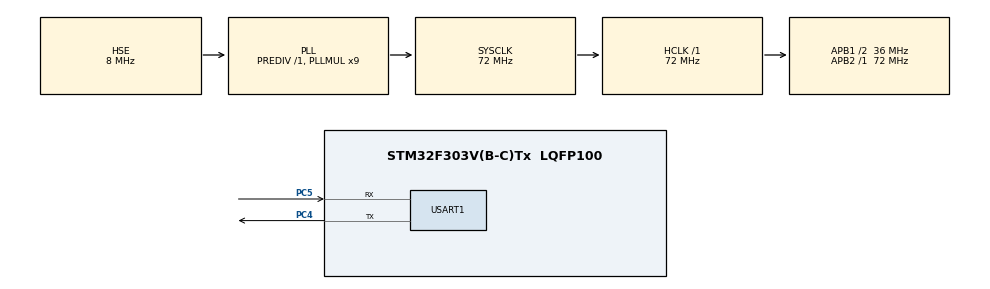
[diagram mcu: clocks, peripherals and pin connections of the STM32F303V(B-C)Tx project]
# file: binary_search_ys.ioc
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Mcu.Family=STM32F3
Mcu.Name=STM32F303V(B-C)Tx
Mcu.Package=LQFP100
NVIC.PriorityGroup=NVIC_PRIORITYGROUP_4
NVIC.TIM2_IRQn=true\:0\:0\:false\:false\:true\:true\:true
PA13.Mode=Serial_Wire
PA13.Signal=SYS_JTMS-SWDIO
PA14.Mode=Serial_Wire
PA14.Signal=SYS_JTCK-SWCLK
PC4.Mode=Asynchronous
PC4.Signal=USART1_TX
PC5.Mode=Asynchronous
PC5.Signal=USART1_RX
PF0-OSC_IN.Mode=HSE-External-Oscillator
PF0-OSC_IN.Signal=RCC_OSC_IN
PF1-OSC_OUT.Mode=HSE-External-Oscillator
PF1-OSC_OUT.Signal=RCC_OSC_OUT
ProjectManager.HeapSize=0x200
ProjectManager.StackSize=0x400
ProjectManager.TargetToolchain=STM32CubeIDE
RCC.AHBFreq_Value=72000000
RCC.APB1CLKDivider=RCC_HCLK_DIV2
RCC.APB1Freq_Value=36000000
RCC.APB1TimFreq_Value=72000000
RCC.APB2Freq_Value=72000000
RCC.APB2TimFreq_Value=72000000
RCC.CortexFreq_Value=72000000
RCC.HCLKFreq_Value=72000000
RCC.HSE_VALUE=8000000
RCC.HSI_VALUE=8000000
RCC.LSE_VALUE=32768
RCC.PLLMUL=RCC_PLL_MUL9
RCC.PLLSourceVirtual=RCC_PLLSOURCE_HSE
RCC.SYSCLKFreq_VALUE=72000000
RCC.SYSCLKSourceVirtual=RCC_SYSCLKSOURCE_PLLCLK
RCC.USBFreq_Value=72000000
TIM2.AutoReloadPreload=TIM_AUTORELOAD_PRELOAD_ENABLE
TIM2.Period=4294967295
TIM2.Prescaler=0
USART1.Parity=PARITY_EVEN
USART1.VirtualMode-Asynchronous=VM_ASYNC
VP_TIM2_VS_ClockSourceINT.Mode=Internal
board=custom

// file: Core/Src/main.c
/* USER CODE BEGIN Header */
/**
  ******************************************************************************
  * @file           : main.c
  * @brief          : Main program body
  ******************************************************************************
  * @attention
  *
  * <h2><center>&copy; Copyright (c) 2022 STMicroelectronics.
  * All rights reserved.</center></h2>
  *
  * This software component is licensed by ST under BSD 3-Clause license,
  * the "License"; You may not use this file except in compliance with the
  * License. You may obtain a copy of the License at:
  *                        opensource.org/licenses/BSD-3-Clause
  *
  ******************************************************************************
  */
/**
 * Binary Search
 * */
/* USER CODE END Header */
#include "main.h"

/* USER CODE BEGIN Includes */
#include <stdio.h>
/* USER CODE END Includes */

/* USER CODE BEGIN PD */
struct DATA {
  int  key;
  int  value;
}  ;

/* USER CODE END PD */

TIM_HandleTypeDef htim2;

UART_HandleTypeDef huart1;

/* USER CODE BEGIN PV */
//struct DATA* dataINccm = 0x1000008c; /*0x10000000+140*/

#if(DATAINFLASH)
const
#endif
#if(DATAINCCMRAM)
__attribute__((section(".ccmramdata")))
#endif
struct DATA data_org[512] = { {1, 100}, {2, 200}, {3, 300}, {4, 400}, {5, 500}, {6, 600}, {7, 700}, {8, 800}, {9, 900}, {10, 1000}, {11, 1100}, {12, 1200}, {13, 1300}, {14, 1400}, {15, 1500}, {16, 1600}, {17, 1700}, {18, 1800}, {19, 1900}, {20, 2000}, {21, 2100}, {22, 2200}, {23, 2300}, {24, 2400}, {25, 2500}, {26, 2600}, {27, 2700}, {28, 2800}, {29, 2900}, {30, 3000}, {31, 3100}, {32, 3200}, {33, 3300}, {34, 3400}, {35, 3500}, {36, 3600}, {37, 3700}, {38, 3800}, {39, 3900}, {40, 4000}, {41, 4100}, {42, 4200}, {43, 4300}, {44, 4400}, {45, 4500}, {46, 4600}, {47, 4700}, {48, 4800}, {49, 4900}, {50, 5000},
		 {51, 5100}, {52, 5200}, {53, 5300}, {54, 5400}, {55, 5500}, {56, 5600}, {57, 5700}, {58, 5800}, {59, 5900}, {60, 6000}, {61, 6100}, {62, 6200}, {63, 6300}, {64, 6400}, {65, 6500}, {66, 6600}, {67, 6700}, {68, 6800}, {69, 6900}, {70, 7000}, {71, 7100}, {72, 7200}, {73, 7300}, {74, 7400}, {75, 7500}, {76, 7600}, {77, 7700}, {78, 7800}, {79, 7900}, {80, 8000}, {81, 8100}, {82, 8200}, {83, 8300}, {84, 8400}, {85, 8500}, {86, 8600}, {87, 8700}, {88, 8800}, {89, 8900}, {90, 9000}, {91, 9100}, {92, 9200}, {93, 9300}, {94, 9400}, {95, 9500}, {96, 9600}, {97, 9700}, {98, 9800}, {99, 9900}, {100, 10000},
		 {101, 10100}, {102, 10200}, {103, 10300}, {104, 10400}, {105, 10500}, {106, 10600}, {107, 10700}, {108, 10800}, {109, 10900}, {110, 11000}, {111, 11100}, {112, 11200}, {113, 11300}, {114, 11400}, {115, 11500}, {116, 11600}, {117, 11700}, {118, 11800}, {119, 11900}, {120, 12000}, {121, 12100}, {122, 12200}, {123, 12300}, {124, 12400}, {125, 12500}, {126, 12600}, {127, 12700}, {128, 12800}, {129, 12900}, {130, 13000}, {131, 13100}, {132, 13200}, {133, 13300}, {134, 13400}, {135, 13500}, {136, 13600}, {137, 13700}, {138, 13800}, {139, 13900}, {140, 14000}, {141, 14100}, {142, 14200}, {143, 14300}, {144, 14400}, {145, 14500}, {146, 14600}, {147, 14700}, {148, 14800}, {149, 14900}, {150, 15000},
		 {151, 15100}, {152, 15200}, {153, 15300}, {154, 15400}, {155, 15500}, {156, 15600}, {157, 15700}, {158, 15800}, {159, 15900}, {160, 16000}, {161, 16100}, {162, 16200}, {163, 16300}, {164, 16400}, {165, 16500}, {166, 16600}, {167, 16700}, {168, 16800}, {169, 16900}, {170, 17000}, {171, 17100}, {172, 17200}, {173, 17300}, {174, 17400}, {175, 17500}, {176, 17600}, {177, 17700}, {178, 17800}, {179, 17900}, {180, 18000}, {181, 18100}, {182, 18200}, {183, 18300}, {184, 18400}, {185, 18500}, {186, 18600}, {187, 18700}, {188, 18800}, {189, 18900}, {190, 19000}, {191, 19100}, {192, 19200}, {193, 19300}, {194, 19400}, {195, 19500}, {196, 19600}, {197, 19700}, {198, 19800}, {199, 19900}, {200, 20000},
		 {201, 20100}, {202, 20200}, {203, 20300}, {204, 20400}, {205, 20500}, {206, 20600}, {207, 20700}, {208, 20800}, {209, 20900}, {210, 21000}, {211, 21100}, {212, 21200}, {213, 21300}, {214, 21400}, {215, 21500}, {216, 21600}, {217, 21700}, {218, 21800}, {219, 21900}, {220, 22000}, {221, 22100}, {222, 22200}, {223, 22300}, {224, 22400}, {225, 22500}, {226, 22600}, {227, 22700}, {228, 22800}, {229, 22900}, {230, 23000}, {231, 23100}, {232, 23200}, {233, 23300}, {234, 23400}, {235, 23500}, {236, 23600}, {237, 23700}, {238, 23800}, {239, 23900}, {240, 24000}, {241, 24100}, {242, 24200}, {243, 24300}, {244, 24400}, {245, 24500}, {246, 24600}, {247, 24700}, {248, 24800}, {249, 24900}, {250, 25000},
		 {251, 25100}, {252, 25200}, {253, 25300}, {254, 25400}, {255, 25500}, {256, 25600}, {257, 25700}, {258, 25800}, {259, 25900}, {260, 26000}, {261, 26100}, {262, 26200}, {263, 26300}, {264, 26400}, {265, 26500}, {266, 26600}, {267, 26700}, {268, 26800}, {269, 26900}, {270, 27000}, {271, 27100}, {272, 27200}, {273, 27300}, {274, 27400}, {275, 27500}, {276, 27600}, {277, 27700}, {278, 27800}, {279, 27900}, {280, 28000}, {281, 28100}, {282, 28200}, {283, 28300}, {284, 28400}, {285, 28500}, {286, 28600}, {287, 28700}, {288, 28800}, {289, 28900}, {290, 29000}, {291, 29100}, {292, 29200}, {293, 29300}, {294, 29400}, {295, 29500}, {296, 29600}, {297, 29700}, {298, 29800}, {299, 29900}, {300, 30000},
		 {301, 30100}, {302, 30200}, {303, 30300}, {304, 30400}, {305, 30500}, {306, 30600}, {307, 30700}, {308, 30800}, {309, 30900}, {310, 31000}, {311, 31100}, {312, 31200}, {313, 31300}, {314, 31400}, {315, 31500}, {316, 31600}, {317, 31700}, {318, 31800}, {319, 31900}, {320, 32000}, {321, 32100}, {322, 32200}, {323, 32300}, {324, 32400}, {325, 32500}, {326, 32600}, {327, 32700}, {328, 32800}, {329, 32900}, {330, 33000}, {331, 33100}, {332, 33200}, {333, 33300}, {334, 33400}, {335, 33500}, {336, 33600}, {337, 33700}, {338, 33800}, {339, 33900}, {340, 34000}, {341, 34100}, {342, 34200}, {343, 34300}, {344, 34400}, {345, 34500}, {346, 34600}, {347, 34700}, {348, 34800}, {349, 34900}, {350, 35000},
		 {351, 35100}, {352, 35200}, {353, 35300}, {354, 35400}, {355, 35500}, {356, 35600}, {357, 35700}, {358, 35800}, {359, 35900}, {360, 36000}, {361, 36100}, {362, 36200}, {363, 36300}, {364, 36400}, {365, 36500}, {366, 36600}, {367, 36700}, {368, 36800}, {369, 36900}, {370, 37000}, {371, 37100}, {372, 37200}, {373, 37300}, {374, 37400}, {375, 37500}, {376, 37600}, {377, 37700}, {378, 37800}, {379, 37900}, {380, 38000}, {381, 38100}, {382, 38200}, {383, 38300}, {384, 38400}, {385, 38500}, {386, 38600}, {387, 38700}, {388, 38800}, {389, 38900}, {390, 39000}, {391, 39100}, {392, 39200}, {393, 39300}, {394, 39400}, {395, 39500}, {396, 39600}, {397, 39700}, {398, 39800}, {399, 39900}, {400, 40000},
		 {401, 40100}, {402, 40200}, {403, 40300}, {404, 40400}, {405, 40500}, {406, 40600}, {407, 40700}, {408, 40800}, {409, 40900}, {410, 41000}, {411, 41100}, {412, 41200}, {413, 41300}, {414, 41400}, {415, 41500}, {416, 41600}, {417, 41700}, {418, 41800}, {419, 41900}, {420, 42000}, {421, 42100}, {422, 42200}, {423, 42300}, {424, 42400}, {425, 42500}, {426, 42600}, {427, 42700}, {428, 42800}, {429, 42900}, {430, 43000}, {431, 43100}, {432, 43200}, {433, 43300}, {434, 43400}, {435, 43500}, {436, 43600}, {437, 43700}, {438, 43800}, {439, 43900}, {440, 44000}, {441, 44100}, {442, 44200}, {443, 44300}, {444, 44400}, {445, 44500}, {446, 44600}, {447, 44700}, {448, 44800}, {449, 44900}, {450, 45000},
		 {451, 45100}, {452, 45200}, {453, 45300}, {454, 45400}, {455, 45500}, {456, 45600}, {457, 45700}, {458, 45800}, {459, 45900}, {460, 46000}, {461, 46100}, {462, 46200}, {463, 46300}, {464, 46400}, {465, 46500}, {466, 46600}, {467, 46700}, {468, 46800}, {469, 46900}, {470, 47000}, {471, 47100}, {472, 47200}, {473, 47300}, {474, 47400}, {475, 47500}, {476, 47600}, {477, 47700}, {478, 47800}, {479, 47900}, {480, 48000}, {481, 48100}, {482, 48200}, {483, 48300}, {484, 48400}, {485, 48500}, {486, 48600}, {487, 48700}, {488, 48800}, {489, 48900}, {490, 49000}, {491, 49100}, {492, 49200}, {493, 49300}, {494, 49400}, {495, 49500}, {496, 49600}, {497, 49700}, {498, 49800}, {499, 49900}, {500, 50000},
		 {501, 50100}, {502, 50200}, {503, 50300}, {504, 50400}, {505, 50500}, {506, 50600}, {507, 50700}, {508, 50800}, {509, 50900}, {510, 51000}, {511, 51100}, {512, 51200}/*, {513, 51300}, {514, 51400}, {515, 51500}, {516, 51600}, {517, 51700}, {518, 51800}, {519, 51900}, {520, 52000}, {521, 52100}, {522, 52200}, {523, 52300}, {524, 52400}, {525, 52500}, {526, 52600}, {527, 52700}, {528, 52800}, {529, 52900}, {530, 53000}, {531, 53100}, {532, 53200}, {533, 53300}, {534, 53400}, {535, 53500}, {536, 53600}, {537, 53700}, {538, 53800}, {539, 53900}, {540, 54000}, {541, 54100}, {542, 54200}, {543, 54300}, {544, 54400}, {545, 54500}, {546, 54600}, {547, 54700}, {548, 54800}, {549, 54900}, {550, 55000},
		 {551, 55100}, {552, 55200}, {553, 55300}, {554, 55400}, {555, 55500}, {556, 55600}, {557, 55700}, {558, 55800}, {559, 55900}, {560, 56000}, {561, 56100}, {562, 56200}, {563, 56300}, {564, 56400}, {565, 56500}, {566, 56600}, {567, 56700}, {568, 56800}, {569, 56900}, {570, 57000}, {571, 57100}, {572, 57200}, {573, 57300}, {574, 57400}, {575, 57500}, {576, 57600}, {577, 57700}, {578, 57800}, {579, 57900}, {580, 58000}, {581, 58100}, {582, 58200}, {583, 58300}, {584, 58400}, {585, 58500}, {586, 58600}, {587, 58700}, {588, 58800}, {589, 58900}, {590, 59000}, {591, 59100}, {592, 59200}, {593, 59300}, {594, 59400}, {595, 59500}, {596, 59600}, {597, 59700}, {598, 59800}, {599, 59900}, {600, 60000},
		 {601, 60100}, {602, 60200}, {603, 60300}, {604, 60400}, {605, 60500}, {606, 60600}, {607, 60700}, {608, 60800}, {609, 60900}, {610, 61000}, {611, 61100}, {612, 61200}, {613, 61300}, {614, 61400}, {615, 61500}, {616, 61600}, {617, 61700}, {618, 61800}, {619, 61900}, {620, 62000}, {621, 62100}, {622, 62200}, {623, 62300}, {624, 62400}, {625, 62500}, {626, 62600}, {627, 62700}, {628, 62800}, {629, 62900}, {630, 63000}, {631, 63100}, {632, 63200}, {633, 63300}, {634, 63400}, {635, 63500}, {636, 63600}, {637, 63700}, {638, 63800}, {639, 63900}, {640, 64000}, {641, 64100}, {642, 64200}, {643, 64300}, {644, 64400}, {645, 64500}, {646, 64600}, {647, 64700}, {648, 64800}, {649, 64900}, {650, 65000},
		 {651, 65100}, {652, 65200}, {653, 65300}, {654, 65400}, {655, 65500}, {656, 65600}, {657, 65700}, {658, 65800}, {659, 65900}, {660, 66000}, {661, 66100}, {662, 66200}, {663, 66300}, {664, 66400}, {665, 66500}, {666, 66600}, {667, 66700}, {668, 66800}, {669, 66900}, {670, 67000}, {671, 67100}, {672, 67200}, {673, 67300}, {674, 67400}, {675, 67500}, {676, 67600}, {677, 67700}, {678, 67800}, {679, 67900}, {680, 68000}, {681, 68100}, {682, 68200}, {683, 68300}, {684, 68400}, {685, 68500}, {686, 68600}, {687, 68700}, {688, 68800}, {689, 68900}, {690, 69000}, {691, 69100}, {692, 69200}, {693, 69300}, {694, 69400}, {695, 69500}, {696, 69600}, {697, 69700}, {698, 69800}, {699, 69900}, {700, 70000},
		 {701, 70100}, {702, 70200}, {703, 70300}, {704, 70400}, {705, 70500}, {706, 70600}, {707, 70700}, {708, 70800}, {709, 70900}, {710, 71000}, {711, 71100}, {712, 71200}, {713, 71300}, {714, 71400}, {715, 71500}, {716, 71600}, {717, 71700}, {718, 71800}, {719, 71900}, {720, 72000}, {721, 72100}, {722, 72200}, {723, 72300}, {724, 72400}, {725, 72500}, {726, 72600}, {727, 72700}, {728, 72800}, {729, 72900}, {730, 73000}, {731, 73100}, {732, 73200}, {733, 73300}, {734, 73400}, {735, 73500}, {736, 73600}, {737, 73700}, {738, 73800}, {739, 73900}, {740, 74000}, {741, 74100}, {742, 74200}, {743, 74300}, {744, 74400}, {745, 74500}, {746, 74600}, {747, 74700}, {748, 74800}, {749, 74900}, {750, 75000},
		 {751, 75100}, {752, 75200}, {753, 75300}, {754, 75400}, {755, 75500}, {756, 75600}, {757, 75700}, {758, 75800}, {759, 75900}, {760, 76000}, {761, 76100}, {762, 76200}, {763, 76300}, {764, 76400}, {765, 76500}, {766, 76600}, {767, 76700}, {768, 76800}, {769, 76900}, {770, 77000}, {771, 77100}, {772, 77200}, {773, 77300}, {774, 77400}, {775, 77500}, {776, 77600}, {777, 77700}, {778, 77800}, {779, 77900}, {780, 78000}, {781, 78100}, {782, 78200}, {783, 78300}, {784, 78400}, {785, 78500}, {786, 78600}, {787, 78700}, {788, 78800}, {789, 78900}, {790, 79000}, {791, 79100}, {792, 79200}, {793, 79300}, {794, 79400}, {795, 79500}, {796, 79600}, {797, 79700}, {798, 79800}, {799, 79900}, {800, 80000},
		 {801, 80100}, {802, 80200}, {803, 80300}, {804, 80400}, {805, 80500}, {806, 80600}, {807, 80700}, {808, 80800}, {809, 80900}, {810, 81000}, {811, 81100}, {812, 81200}, {813, 81300}, {814, 81400}, {815, 81500}, {816, 81600}, {817, 81700}, {818, 81800}, {819, 81900}, {820, 82000}, {821, 82100}, {822, 82200}, {823, 82300}, {824, 82400}, {825, 82500}, {826, 82600}, {827, 82700}, {828, 82800}, {829, 82900}, {830, 83000}, {831, 83100}, {832, 83200}, {833, 83300}, {834, 83400}, {835, 83500}, {836, 83600}, {837, 83700}, {838, 83800}, {839, 83900}, {840, 84000}, {841, 84100}, {842, 84200}, {843, 84300}, {844, 84400}, {845, 84500}, {846, 84600}, {847, 84700}, {848, 84800}, {849, 84900}, {850, 85000},
		 {851, 85100}, {852, 85200}, {853, 85300}, {854, 85400}, {855, 85500}, {856, 85600}, {857, 85700}, {858, 85800}, {859, 85900}, {860, 86000}, {861, 86100}, {862, 86200}, {863, 86300}, {864, 86400}, {865, 86500}, {866, 86600}, {867, 86700}, {868, 86800}, {869, 86900}, {870, 87000}, {871, 87100}, {872, 87200}, {873, 87300}, {874, 87400}, {875, 87500}, {876, 87600}, {877, 87700}, {878, 87800}, {879, 87900}, {880, 88000}, {881, 88100}, {882, 88200}, {883, 88300}, {884, 88400}, {885, 88500}, {886, 88600}, {887, 88700}, {888, 88800}, {889, 88900}, {890, 89000}, {891, 89100}, {892, 89200}, {893, 89300}, {894, 89400}, {895, 89500}, {896, 89600}, {897, 89700}, {898, 89800}, {899, 89900}, {900, 90000},
		 {901, 90100}, {902, 90200}, {903, 90300}, {904, 90400}, {905, 90500}, {906, 90600}, {907, 90700}, {908, 90800}, {909, 90900}, {910, 91000}, {911, 91100}, {912, 91200}, {913, 91300}, {914, 91400}, {915, 91500}, {916, 91600}, {917, 91700}, {918, 91800}, {919, 91900}, {920, 92000}, {921, 92100}, {922, 92200}, {923, 92300}, {924, 92400}, {925, 92500}, {926, 92600}, {927, 92700}, {928, 92800}, {929, 92900}, {930, 93000}, {931, 93100}, {932, 93200}, {933, 93300}, {934, 93400}, {935, 93500}, {936, 93600}, {937, 93700}, {938, 93800}, {939, 93900}, {940, 94000}, {941, 94100}, {942, 94200}, {943, 94300}, {944, 94400}, {945, 94500}, {946, 94600}, {947, 94700}, {948, 94800}, {949, 94900}, {950, 95000},
		 {951, 95100}, {952, 95200}, {953, 95300}, {954, 95400}, {955, 95500}, {956, 95600}, {957, 95700}, {958, 95800}, {959, 95900}, {960, 96000}, {961, 96100}, {962, 96200}, {963, 96300}, {964, 96400}, {965, 96500}, {966, 96600}, {967, 96700}, {968, 96800}, {969, 96900}, {970, 97000}, {971, 97100}, {972, 97200}, {973, 97300}, {974, 97400}, {975, 97500}, {976, 97600}, {977, 97700}, {978, 97800}, {979, 97900}, {980, 98000}, {981, 98100}, {982, 98200}, {983, 98300}, {984, 98400}, {985, 98500}, {986, 98600}, {987, 98700}, {988, 98800}, {989, 98900}, {990, 99000}, {991, 99100}, {992, 99200}, {993, 99300}, {994, 99400}, {995, 99500}, {996, 99600}, {997, 99700}, {998, 99800}, {999, 99900}, {1000, 100000},
		 {1001, 100100}, {1002, 100200}, {1003, 100300}, {1004, 100400}, {1005, 100500}, {1006, 100600}, {1007, 100700}, {1008, 100800}, {1009, 100900}, {1010, 101000}, {1011, 101100}, {1012, 101200}, {1013, 101300}, {1014, 101400}, {1015, 101500}, {1016, 101600}, {1017, 101700}, {1018, 101800}, {1019, 101900}, {1020, 102000}, {1021, 102100}, {1022, 102200}, {1023, 102300}, {1024, 102400}, {1025, 102500}, {1026, 102600}, {1027, 102700}, {1028, 102800}, {1029, 102900}, {1030, 103000}, {1031, 103100}, {1032, 103200}, {1033, 103300}, {1034, 103400}, {1035, 103500}, {1036, 103600}, {1037, 103700}, {1038, 103800}, {1039, 103900}, {1040, 104000}, {1041, 104100}, {1042, 104200}, {1043, 104300}, {1044, 104400}, {1045, 104500}, {1046, 104600}, {1047, 104700}, {1048, 104800}, {1049, 104900}, {1050, 105000},
		 {1051, 105100}, {1052, 105200}, {1053, 105300}, {1054, 105400}, {1055, 105500}, {1056, 105600}, {1057, 105700}, {1058, 105800}, {1059, 105900}, {1060, 106000}, {1061, 106100}, {1062, 106200}, {1063, 106300}, {1064, 106400}, {1065, 106500}, {1066, 106600}, {1067, 106700}, {1068, 106800}, {1069, 106900}, {1070, 107000}, {1071, 107100}, {1072, 107200}, {1073, 107300}, {1074, 107400}, {1075, 107500}, {1076, 107600}, {1077, 107700}, {1078, 107800}, {1079, 107900}, {1080, 108000}, {1081, 108100}, {1082, 108200}, {1083, 108300}, {1084, 108400}, {1085, 108500}, {1086, 108600}, {1087, 108700}, {1088, 108800}, {1089, 108900}, {1090, 109000}, {1091, 109100}, {1092, 109200}, {1093, 109300}, {1094, 109400}, {1095, 109500}, {1096, 109600}, {1097, 109700}, {1098, 109800}, {1099, 109900}, {1100, 110000},
		 {1101, 110100}, {1102, 110200}, {1103, 110300}, {1104, 110400}, {1105, 110500}, {1106, 110600}, {1107, 110700}, {1108, 110800}, {1109, 110900}, {1110, 111000}, {1111, 111100}, {1112, 111200}, {1113, 111300}, {1114, 111400}, {1115, 111500}, {1116, 111600}, {1117, 111700}, {1118, 111800}, {1119, 111900}, {1120, 112000}, {1121, 112100}, {1122, 112200}, {1123, 112300}, {1124, 112400}, {1125, 112500}, {1126, 112600}, {1127, 112700}, {1128, 112800}, {1129, 112900}, {1130, 113000}, {1131, 113100}, {1132, 113200}, {1133, 113300}, {1134, 113400}, {1135, 113500}, {1136, 113600}, {1137, 113700}, {1138, 113800}, {1139, 113900}, {1140, 114000}, {1141, 114100}, {1142, 114200}, {1143, 114300}, {1144, 114400}, {1145, 114500}, {1146, 114600}, {1147, 114700}, {1148, 114800}, {1149, 114900}, {1150, 115000},
		 {1151, 115100}, {1152, 115200}, {1153, 115300}, {1154, 115400}, {1155, 115500}, {1156, 115600}, {1157, 115700}, {1158, 115800}, {1159, 115900}, {1160, 116000}, {1161, 116100}, {1162, 116200}, {1163, 116300}, {1164, 116400}, {1165, 116500}, {1166, 116600}, {1167, 116700}, {1168, 116800}, {1169, 116900}, {1170, 117000}, {1171, 117100}, {1172, 117200}, {1173, 117300}, {1174, 117400}, {1175, 117500}, {1176, 117600}, {1177, 117700}, {1178, 117800}, {1179, 117900}, {1180, 118000}, {1181, 118100}, {1182, 118200}, {1183, 118300}, {1184, 118400}, {1185, 118500}, {1186, 118600}, {1187, 118700}, {1188, 118800}, {1189, 118900}, {1190, 119000}, {1191, 119100}, {1192, 119200}, {1193, 119300}, {1194, 119400}, {1195, 119500}, {1196, 119600}, {1197, 119700}, {1198, 119800}, {1199, 119900}, {1200, 120000},
		 {1201, 120100}, {1202, 120200}, {1203, 120300}, {1204, 120400}, {1205, 120500}, {1206, 120600}, {1207, 120700}, {1208, 120800}, {1209, 120900}, {1210, 121000}, {1211, 121100}, {1212, 121200}, {1213, 121300}, {1214, 121400}, {1215, 121500}, {1216, 121600}, {1217, 121700}, {1218, 121800}, {1219, 121900}, {1220, 122000}, {1221, 122100}, {1222, 122200}, {1223, 122300}, {1224, 122400}, {1225, 122500}, {1226, 122600}, {1227, 122700}, {1228, 122800}, {1229, 122900}, {1230, 123000}, {1231, 123100}, {1232, 123200}, {1233, 123300}, {1234, 123400}, {1235, 123500}, {1236, 123600}, {1237, 123700}, {1238, 123800}, {1239, 123900}, {1240, 124000}, {1241, 124100}, {1242, 124200}, {1243, 124300}, {1244, 124400}, {1245, 124500}, {1246, 124600}, {1247, 124700}, {1248, 124800}, {1249, 124900}, {1250, 125000},
		 {1251, 125100}, {1252, 125200}, {1253, 125300}, {1254, 125400}, {1255, 125500}, {1256, 125600}, {1257, 125700}, {1258, 125800}, {1259, 125900}, {1260, 126000}, {1261, 126100}, {1262, 126200}, {1263, 126300}, {1264, 126400}, {1265, 126500}, {1266, 126600}, {1267, 126700}, {1268, 126800}, {1269, 126900}, {1270, 127000}, {1271, 127100}, {1272, 127200}, {1273, 127300}, {1274, 127400}, {1275, 127500}, {1276, 127600}, {1277, 127700}, {1278, 127800}, {1279, 127900}, {1280, 128000}, {1281, 128100}, {1282, 128200}, {1283, 128300}, {1284, 128400}, {1285, 128500}, {1286, 128600}, {1287, 128700}, {1288, 128800}, {1289, 128900}, {1290, 129000}, {1291, 129100}, {1292, 129200}, {1293, 129300}, {1294, 129400}, {1295, 129500}, {1296, 129600}, {1297, 129700}, {1298, 129800}, {1299, 129900}, {1300, 130000},
		 {1301, 130100}, {1302, 130200}, {1303, 130300}, {1304, 130400}, {1305, 130500}, {1306, 130600}, {1307, 130700}, {1308, 130800}, {1309, 130900}, {1310, 131000}, {1311, 131100}, {1312, 131200}, {1313, 131300}, {1314, 131400}, {1315, 131500}, {1316, 131600}, {1317, 131700}, {1318, 131800}, {1319, 131900}, {1320, 132000}, {1321, 132100}, {1322, 132200}, {1323, 132300}, {1324, 132400}, {1325, 132500}, {1326, 132600}, {1327, 132700}, {1328, 132800}, {1329, 132900}, {1330, 133000}, {1331, 133100}, {1332, 133200}, {1333, 133300}, {1334, 133400}, {1335, 133500}, {1336, 133600}, {1337, 133700}, {1338, 133800}, {1339, 133900}, {1340, 134000}, {1341, 134100}, {1342, 134200}, {1343, 134300}, {1344, 134400}, {1345, 134500}, {1346, 134600}, {1347, 134700}, {1348, 134800}, {1349, 134900}, {1350, 135000},
		 {1351, 135100}, {1352, 135200}, {1353, 135300}, {1354, 135400}, {1355, 135500}, {1356, 135600}, {1357, 135700}, {1358, 135800}, {1359, 135900}, {1360, 136000}, {1361, 136100}, {1362, 136200}, {1363, 136300}, {1364, 136400}, {1365, 136500}, {1366, 136600}, {1367, 136700}, {1368, 136800}, {1369, 136900}, {1370, 137000}, {1371, 137100}, {1372, 137200}, {1373, 137300}, {1374, 137400}, {1375, 137500}, {1376, 137600}, {1377, 137700}, {1378, 137800}, {1379, 137900}, {1380, 138000}, {1381, 138100}, {1382, 138200}, {1383, 138300}, {1384, 138400}, {1385, 138500}, {1386, 138600}, {1387, 138700}, {1388, 138800}, {1389, 138900}, {1390, 139000}, {1391, 139100}, {1392, 139200}, {1393, 139300}, {1394, 139400}, {1395, 139500}, {1396, 139600}, {1397, 139700}, {1398, 139800}, {1399, 139900}, {1400, 140000},
		 {1401, 140100}, {1402, 140200}, {1403, 140300}, {1404, 140400}, {1405, 140500}, {1406, 140600}, {1407, 140700}, {1408, 140800}, {1409, 140900}, {1410, 141000}, {1411, 141100}, {1412, 141200}, {1413, 141300}, {1414, 141400}, {1415, 141500}, {1416, 141600}, {1417, 141700}, {1418, 141800}, {1419, 141900}, {1420, 142000}, {1421, 142100}, {1422, 142200}, {1423, 142300}, {1424, 142400}, {1425, 142500}, {1426, 142600}, {1427, 142700}, {1428, 142800}, {1429, 142900}, {1430, 143000}, {1431, 143100}, {1432, 143200}, {1433, 143300}, {1434, 143400}, {1435, 143500}, {1436, 143600}, {1437, 143700}, {1438, 143800}, {1439, 143900}, {1440, 144000}, {1441, 144100}, {1442, 144200}, {1443, 144300}, {1444, 144400}, {1445, 144500}, {1446, 144600}, {1447, 144700}, {1448, 144800}, {1449, 144900}, {1450, 145000},
		 {1451, 145100}, {1452, 145200}, {1453, 145300}, {1454, 145400}, {1455, 145500}, {1456, 145600}, {1457, 145700}, {1458, 145800}, {1459, 145900}, {1460, 146000}, {1461, 146100}, {1462, 146200}, {1463, 146300}, {1464, 146400}, {1465, 146500}, {1466, 146600}, {1467, 146700}, {1468, 146800}, {1469, 146900}, {1470, 147000}, {1471, 147100}, {1472, 147200}, {1473, 147300}, {1474, 147400}, {1475, 147500}, {1476, 147600}, {1477, 147700}, {1478, 147800}, {1479, 147900}, {1480, 148000}, {1481, 148100}, {1482, 148200}, {1483, 148300}, {1484, 148400}, {1485, 148500}, {1486, 148600}, {1487, 148700}, {1488, 148800}, {1489, 148900}, {1490, 149000}, {1491, 149100}, {1492, 149200}, {1493, 149300}, {1494, 149400}, {1495, 149500}, {1496, 149600}, {1497, 149700}, {1498, 149800}, {1499, 149900}, {1500, 150000},
		 {1501, 150100}, {1502, 150200}, {1503, 150300}, {1504, 150400}, {1505, 150500}, {1506, 150600}, {1507, 150700}, {1508, 150800}, {1509, 150900}, {1510, 151000}, {1511, 151100}, {1512, 151200}, {1513, 151300}, {1514, 151400}, {1515, 151500}, {1516, 151600}, {1517, 151700}, {1518, 151800}, {1519, 151900}, {1520, 152000}, {1521, 152100}, {1522, 152200}, {1523, 152300}, {1524, 152400}, {1525, 152500}, {1526, 152600}, {1527, 152700}, {1528, 152800}, {1529, 152900}, {1530, 153000}, {1531, 153100}, {1532, 153200}, {1533, 153300}, {1534, 153400}, {1535, 153500}, {1536, 153600}, {1537, 153700}, {1538, 153800}, {1539, 153900}, {1540, 154000}, {1541, 154100}, {1542, 154200}, {1543, 154300}, {1544, 154400}, {1545, 154500}, {1546, 154600}, {1547, 154700}, {1548, 154800}, {1549, 154900}, {1550, 155000},
		 {1551, 155100}, {1552, 155200}, {1553, 155300}, {1554, 155400}, {1555, 155500}, {1556, 155600}, {1557, 155700}, {1558, 155800}, {1559, 155900}, {1560, 156000}, {1561, 156100}, {1562, 156200}, {1563, 156300}, {1564, 156400}, {1565, 156500}, {1566, 156600}, {1567, 156700}, {1568, 156800}, {1569, 156900}, {1570, 157000}, {1571, 157100}, {1572, 157200}, {1573, 157300}, {1574, 157400}, {1575, 157500}, {1576, 157600}, {1577, 157700}, {1578, 157800}, {1579, 157900}, {1580, 158000}, {1581, 158100}, {1582, 158200}, {1583, 158300}, {1584, 158400}, {1585, 158500}, {1586, 158600}, {1587, 158700}, {1588, 158800}, {1589, 158900}, {1590, 159000}, {1591, 159100}, {1592, 159200}, {1593, 159300}, {1594, 159400}, {1595, 159500}, {1596, 159600}, {1597, 159700}, {1598, 159800}, {1599, 159900}, {1600, 160000},
		 {1601, 160100}, {1602, 160200}, {1603, 160300}, {1604, 160400}, {1605, 160500}, {1606, 160600}, {1607, 160700}, {1608, 160800}, {1609, 160900}, {1610, 161000}, {1611, 161100}, {1612, 161200}, {1613, 161300}, {1614, 161400}, {1615, 161500}, {1616, 161600}, {1617, 161700}, {1618, 161800}, {1619, 161900}, {1620, 162000}, {1621, 162100}, {1622, 162200}, {1623, 162300}, {1624, 162400}, {1625, 162500}, {1626, 162600}, {1627, 162700}, {1628, 162800}, {1629, 162900}, {1630, 163000}, {1631, 163100}, {1632, 163200}, {1633, 163300}, {1634, 163400}, {1635, 163500}, {1636, 163600}, {1637, 163700}, {1638, 163800}, {1639, 163900}, {1640, 164000}, {1641, 164100}, {1642, 164200}, {1643, 164300}, {1644, 164400}, {1645, 164500}, {1646, 164600}, {1647, 164700}, {1648, 164800}, {1649, 164900}, {1650, 165000},
		 {1651, 165100}, {1652, 165200}, {1653, 165300}, {1654, 165400}, {1655, 165500}, {1656, 165600}, {1657, 165700}, {1658, 165800}, {1659, 165900}, {1660, 166000}, {1661, 166100}, {1662, 166200}, {1663, 166300}, {1664, 166400}, {1665, 166500}, {1666, 166600}, {1667, 166700}, {1668, 166800}, {1669, 166900}, {1670, 167000}, {1671, 167100}, {1672, 167200}, {1673, 167300}, {1674, 167400}, {1675, 167500}, {1676, 167600}, {1677, 167700}, {1678, 167800}, {1679, 167900}, {1680, 168000}, {1681, 168100}, {1682, 168200}, {1683, 168300}, {1684, 168400}, {1685, 168500}, {1686, 168600}, {1687, 168700}, {1688, 168800}, {1689, 168900}, {1690, 169000}, {1691, 169100}, {1692, 169200}, {1693, 169300}, {1694, 169400}, {1695, 169500}, {1696, 169600}, {1697, 169700}, {1698, 169800}, {1699, 169900}, {1700, 170000},
		 {1701, 170100}, {1702, 170200}, {1703, 170300}, {1704, 170400}, {1705, 170500}, {1706, 170600}, {1707, 170700}, {1708, 170800}, {1709, 170900}, {1710, 171000}, {1711, 171100}, {1712, 171200}, {1713, 171300}, {1714, 171400}, {1715, 171500}, {1716, 171600}, {1717, 171700}, {1718, 171800}, {1719, 171900}, {1720, 172000}, {1721, 172100}, {1722, 172200}, {1723, 172300}, {1724, 172400}, {1725, 172500}, {1726, 172600}, {1727, 172700}, {1728, 172800}, {1729, 172900}, {1730, 173000}, {1731, 173100}, {1732, 173200}, {1733, 173300}, {1734, 173400}, {1735, 173500}, {1736, 173600}, {1737, 173700}, {1738, 173800}, {1739, 173900}, {1740, 174000}, {1741, 174100}, {1742, 174200}, {1743, 174300}, {1744, 174400}, {1745, 174500}, {1746, 174600}, {1747, 174700}, {1748, 174800}, {1749, 174900}, {1750, 175000},
		 {1751, 175100}, {1752, 175200}, {1753, 175300}, {1754, 175400}, {1755, 175500}, {1756, 175600}, {1757, 175700}, {1758, 175800}, {1759, 175900}, {1760, 176000}, {1761, 176100}, {1762, 176200}, {1763, 176300}, {1764, 176400}, {1765, 176500}, {1766, 176600}, {1767, 176700}, {1768, 176800}, {1769, 176900}, {1770, 177000}, {1771, 177100}, {1772, 177200}, {1773, 177300}, {1774, 177400}, {1775, 177500}, {1776, 177600}, {1777, 177700}, {1778, 177800}, {1779, 177900}, {1780, 178000}, {1781, 178100}, {1782, 178200}, {1783, 178300}, {1784, 178400}, {1785, 178500}, {1786, 178600}, {1787, 178700}, {1788, 178800}, {1789, 178900}, {1790, 179000}, {1791, 179100}, {1792, 179200}, {1793, 179300}, {1794, 179400}, {1795, 179500}, {1796, 179600}, {1797, 179700}, {1798, 179800}, {1799, 179900}, {1800, 180000},
		 {1801, 180100}, {1802, 180200}, {1803, 180300}, {1804, 180400}, {1805, 180500}, {1806, 180600}, {1807, 180700}, {1808, 180800}, {1809, 180900}, {1810, 181000}, {1811, 181100}, {1812, 181200}, {1813, 181300}, {1814, 181400}, {1815, 181500}, {1816, 181600}, {1817, 181700}, {1818, 181800}, {1819, 181900}, {1820, 182000}, {1821, 182100}, {1822, 182200}, {1823, 182300}, {1824, 182400}, {1825, 182500}, {1826, 182600}, {1827, 182700}, {1828, 182800}, {1829, 182900}, {1830, 183000}, {1831, 183100}, {1832, 183200}, {1833, 183300}, {1834, 183400}, {1835, 183500}, {1836, 183600}, {1837, 183700}, {1838, 183800}, {1839, 183900}, {1840, 184000}, {1841, 184100}, {1842, 184200}, {1843, 184300}, {1844, 184400}, {1845, 184500}, {1846, 184600}, {1847, 184700}, {1848, 184800}, {1849, 184900}, {1850, 185000},
		 {1851, 185100}, {1852, 185200}, {1853, 185300}, {1854, 185400}, {1855, 185500}, {1856, 185600}, {1857, 185700}, {1858, 185800}, {1859, 185900}, {1860, 186000}, {1861, 186100}, {1862, 186200}, {1863, 186300}, {1864, 186400}, {1865, 186500}, {1866, 186600}, {1867, 186700}, {1868, 186800}, {1869, 186900}, {1870, 187000}, {1871, 187100}, {1872, 187200}, {1873, 187300}, {1874, 187400}, {1875, 187500}, {1876, 187600}, {1877, 187700}, {1878, 187800}, {1879, 187900}, {1880, 188000}, {1881, 188100}, {1882, 188200}, {1883, 188300}, {1884, 188400}, {1885, 188500}, {1886, 188600}, {1887, 188700}, {1888, 188800}, {1889, 188900}, {1890, 189000}, {1891, 189100}, {1892, 189200}, {1893, 189300}, {1894, 189400}, {1895, 189500}, {1896, 189600}, {1897, 189700}, {1898, 189800}, {1899, 189900}, {1900, 190000},
		 {1901, 190100}, {1902, 190200}, {1903, 190300}, {1904, 190400}, {1905, 190500}, {1906, 190600}, {1907, 190700}, {1908, 190800}, {1909, 190900}, {1910, 191000}, {1911, 191100}, {1912, 191200}, {1913, 191300}, {1914, 191400}, {1915, 191500}, {1916, 191600}, {1917, 191700}, {1918, 191800}, {1919, 191900}, {1920, 192000}, {1921, 192100}, {1922, 192200}, {1923, 192300}, {1924, 192400}, {1925, 192500}, {1926, 192600}, {1927, 192700}, {1928, 192800}, {1929, 192900}, {1930, 193000}, {1931, 193100}, {1932, 193200}, {1933, 193300}, {1934, 193400}, {1935, 193500}, {1936, 193600}, {1937, 193700}, {1938, 193800}, {1939, 193900}, {1940, 194000}, {1941, 194100}, {1942, 194200}, {1943, 194300}, {1944, 194400}, {1945, 194500}, {1946, 194600}, {1947, 194700}, {1948, 194800}, {1949, 194900}, {1950, 195000},
		 {1951, 195100}, {1952, 195200}, {1953, 195300}, {1954, 195400}, {1955, 195500}, {1956, 195600}, {1957, 195700}, {1958, 195800}, {1959, 195900}, {1960, 196000}, {1961, 196100}, {1962, 196200}, {1963, 196300}, {1964, 196400}, {1965, 196500}, {1966, 196600}, {1967, 196700}, {1968, 196800}, {1969, 196900}, {1970, 197000}, {1971, 197100}, {1972, 197200}, {1973, 197300}, {1974, 197400}, {1975, 197500}, {1976, 197600}, {1977, 197700}, {1978, 197800}, {1979, 197900}, {1980, 198000}, {1981, 198100}, {1982, 198200}, {1983, 198300}, {1984, 198400}, {1985, 198500}, {1986, 198600}, {1987, 198700}, {1988, 198800}, {1989, 198900}, {1990, 199000}, {1991, 199100}, {1992, 199200}, {1993, 199300}, {1994, 199400}, {1995, 199500}, {1996, 199600}, {1997, 199700}, {1998, 199800}, {1999, 199900}, {2000, 200000},
		 {2001, 200100}, {2002, 200200}, {2003, 200300}, {2004, 200400}, {2005, 200500}, {2006, 200600}, {2007, 200700}, {2008, 200800}, {2009, 200900}, {2010, 201000}, {2011, 201100}, {2012, 201200}, {2013, 201300}, {2014, 201400}, {2015, 201500}, {2016, 201600}, {2017, 201700}, {2018, 201800}, {2019, 201900}, {2020, 202000}, {2021, 202100}, {2022, 202200}, {2023, 202300}, {2024, 202400}, {2025, 202500}, {2026, 202600}, {2027, 202700}, {2028, 202800}, {2029, 202900}, {2030, 203000}, {2031, 203100}, {2032, 203200}, {2033, 203300}, {2034, 203400}, {2035, 203500}, {2036, 203600}, {2037, 203700}, {2038, 203800}, {2039, 203900}, {2040, 204000}, {2041, 204100}, {2042, 204200}, {2043, 204300}, {2044, 204400}, {2045, 204500}, {2046, 204600}, {2047, 204700}, {2048, 204800}
*/};
int keyToFind = 1;
int valueToFind;
int NUMELEMS = 4;
uint8_t loop_counter = 0;
/* USER CODE END PV */

void SystemClock_Config(void);
static void MX_GPIO_Init(void);
static void MX_TIM2_Init(void);
static void MX_USART1_UART_Init(void);
/* USER CODE BEGIN PFP */
#if(CCMRAM)
__attribute__((section(".ccmram")))
#endif
int binary_search(int x)
{
  int fvalue, mid, up, low ;

  low = 0;
  up = NUMELEMS;
  fvalue = -1 /* all data are positive */ ;
  while (low <= up) {
    mid = (low + up) >> 1;
    if (data_org[mid].key == x ) {  /*  found  */
      up = low - 1;
      fvalue = data_org[mid].value;
    }
    else  /* not found */
      if (data_org[mid].key > x ) 	{
	up = mid - 1;
      }
      else   {
             	low = mid + 1;
      }
  }
  return fvalue;
}
/* USER CODE END PFP */

int main(void)
{
  /* USER CODE BEGIN 1 */
  uint8_t gu8_MSG[60] = {'\0'};
  volatile uint32_t time1, time2;
  //memcpy(dataINccm, data_org, 8*512);
  /* USER CODE END 1 */

  /* MCU Configuration--------------------------------------------------------*/

  /* Reset of all peripherals, Initializes the Flash interface and the Systick. */
  HAL_Init();

  /* Configure the system clock */
  SystemClock_Config();

  /* Initialize all configured peripherals */
  MX_GPIO_Init();
  MX_TIM2_Init();
  MX_USART1_UART_Init();
  /* USER CODE BEGIN 2 */
  HAL_TIM_Base_Start(&htim2);
  /* USER CODE END 2 */

  /* Infinite loop */
  while (1)
  {

    /* USER CODE BEGIN 3 */
	time1 = TIM2->CNT;
	valueToFind = binary_search(keyToFind);
	time2 = TIM2->CNT;

	execution_time =(int)((double)(time2-time1)/cpu_frequency*1000);          /* in ns */
	//sprintf(gu8_MSG, "%d\t%d\t%ld\n\r",NUMELEMS,valueToFind, execution_time);
	sprintf(gu8_MSG, "%d\n\r",execution_time);
	HAL_UART_Transmit(&huart1, gu8_MSG, sizeof(gu8_MSG), 0xFFFF);
	HAL_Delay(200);
	if(loop_counter == 0){
		loop_counter++;
	}else if(NUMELEMS < 512){
		NUMELEMS *= 2;
		loop_counter++;
	}else{
		NUMELEMS=4;
		HAL_Delay(2000);
	}
	//memset(dataINccm,0,8*NUMELEMS);
  }
  /* USER CODE END 3 */
}

void SystemClock_Config(void)
{
  RCC_OscInitTypeDef RCC_OscInitStruct = {0};
  RCC_ClkInitTypeDef RCC_ClkInitStruct = {0};
  RCC_PeriphCLKInitTypeDef PeriphClkInit = {0};

  /** Initializes the RCC Oscillators according to the specified parameters
  * in the RCC_OscInitTypeDef structure.
  */
  RCC_OscInitStruct.OscillatorType = RCC_OSCILLATORTYPE_HSE;
  RCC_OscInitStruct.HSEState = RCC_HSE_ON;
  RCC_OscInitStruct.HSEPredivValue = RCC_HSE_PREDIV_DIV1;
  RCC_OscInitStruct.HSIState = RCC_HSI_ON;
  RCC_OscInitStruct.PLL.PLLState = RCC_PLL_ON;
  RCC_OscInitStruct.PLL.PLLSource = RCC_PLLSOURCE_HSE;
  RCC_OscInitStruct.PLL.PLLMUL = RCC_PLL_MUL9;
  if (HAL_RCC_OscConfig(&RCC_OscInitStruct) != HAL_OK)
  {
    Error_Handler();
  }
  /** Initializes the CPU, AHB and APB buses clocks
  */
  RCC_ClkInitStruct.ClockType = RCC_CLOCKTYPE_HCLK|RCC_CLOCKTYPE_SYSCLK
                              |RCC_CLOCKTYPE_PCLK1|RCC_CLOCKTYPE_PCLK2;
  RCC_ClkInitStruct.SYSCLKSource = RCC_SYSCLKSOURCE_PLLCLK;
  RCC_ClkInitStruct.AHBCLKDivider = RCC_SYSCLK_DIV1;
  RCC_ClkInitStruct.APB1CLKDivider = RCC_HCLK_DIV2;
  RCC_ClkInitStruct.APB2CLKDivider = RCC_HCLK_DIV1;

  if (HAL_RCC_ClockConfig(&RCC_ClkInitStruct, FLASH_LATENCY_2) != HAL_OK)
  {
    Error_Handler();
  }
  PeriphClkInit.PeriphClockSelection = RCC_PERIPHCLK_USART1;
  PeriphClkInit.Usart1ClockSelection = RCC_USART1CLKSOURCE_PCLK2;
  if (HAL_RCCEx_PeriphCLKConfig(&PeriphClkInit) != HAL_OK)
  {
    Error_Handler();
  }
}

static void MX_TIM2_Init(void)
{

  TIM_ClockConfigTypeDef sClockSourceConfig = {0};
  TIM_MasterConfigTypeDef sMasterConfig = {0};

  htim2.Instance = TIM2;
  htim2.Init.Prescaler = 0;
  htim2.Init.CounterMode = TIM_COUNTERMODE_UP;
  htim2.Init.Period = 4294967295;
  htim2.Init.ClockDivision = TIM_CLOCKDIVISION_DIV1;
  htim2.Init.AutoReloadPreload = TIM_AUTORELOAD_PRELOAD_ENABLE;
  if (HAL_TIM_Base_Init(&htim2) != HAL_OK)
  {
    Error_Handler();
  }
  sClockSourceConfig.ClockSource = TIM_CLOCKSOURCE_INTERNAL;
  if (HAL_TIM_ConfigClockSource(&htim2, &sClockSourceConfig) != HAL_OK)
  {
    Error_Handler();
  }
  sMasterConfig.MasterOutputTrigger = TIM_TRGO_RESET;
  sMasterConfig.MasterSlaveMode = TIM_MASTERSLAVEMODE_DISABLE;
  if (HAL_TIMEx_MasterConfigSynchronization(&htim2, &sMasterConfig) != HAL_OK)
  {
    Error_Handler();
  }

}

static void MX_USART1_UART_Init(void)
{

  huart1.Instance = USART1;
  huart1.Init.BaudRate = 38400;
  huart1.Init.WordLength = UART_WORDLENGTH_8B;
  huart1.Init.StopBits = UART_STOPBITS_1;
  huart1.Init.Parity = UART_PARITY_EVEN;
  huart1.Init.Mode = UART_MODE_TX_RX;
  huart1.Init.HwFlowCtl = UART_HWCONTROL_NONE;
  huart1.Init.OverSampling = UART_OVERSAMPLING_16;
  huart1.Init.OneBitSampling = UART_ONE_BIT_SAMPLE_DISABLE;
  huart1.AdvancedInit.AdvFeatureInit = UART_ADVFEATURE_NO_INIT;
  if (HAL_UART_Init(&huart1) != HAL_OK)
  {
    Error_Handler();
  }

}

static void MX_GPIO_Init(void)
{

  /* GPIO Ports Clock Enable */
  __HAL_RCC_GPIOF_CLK_ENABLE();
  __HAL_RCC_GPIOC_CLK_ENABLE();
  __HAL_RCC_GPIOA_CLK_ENABLE();

}

void Error_Handler(void)
{
  __disable_irq();
  while (1)
  {
  }
}

/************************ (C) COPYRIGHT STMicroelectronics *****END OF FILE****/
